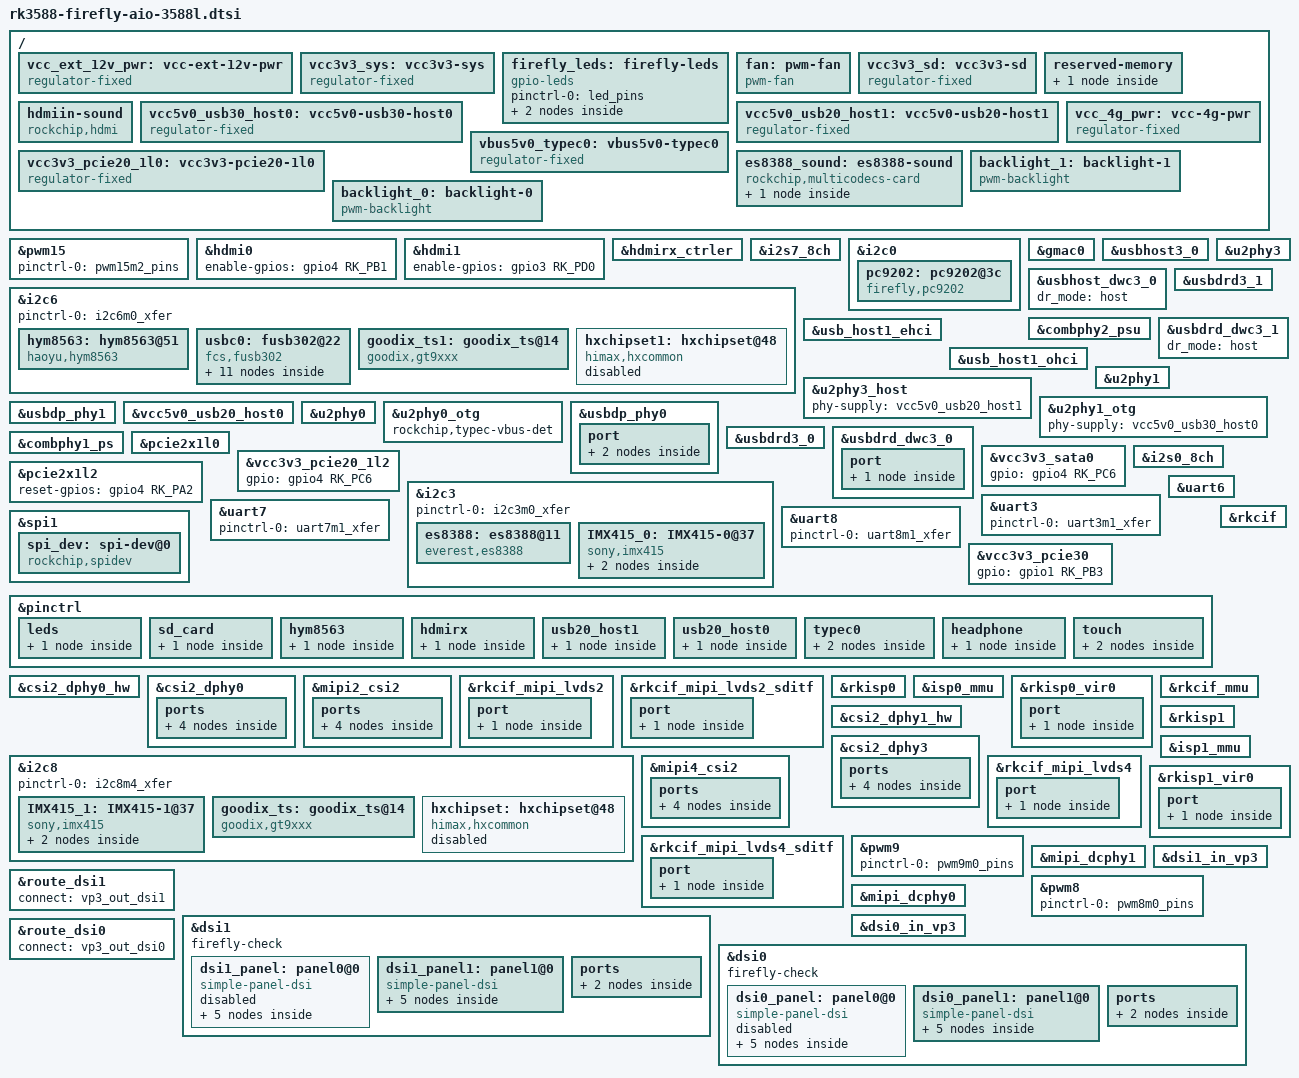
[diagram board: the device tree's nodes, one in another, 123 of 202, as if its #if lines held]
// SPDX-License-Identifier: (GPL-2.0+ OR MIT)
/*
 * Copyright (c) 2022 Rockchip Electronics Co., Ltd.
 *
 */
#include "rk3588-firefly-common.dtsi"

/ {
	vcc_ext_12v_pwr: vcc-ext-12v-pwr {
		status = "okay";
		compatible = "regulator-fixed";
		regulator-name = "vcc_ext_12v_pwr";
		regulator-boot-on;
		regulator-always-on;
		enable-active-high;
		gpio = <&gpio0 RK_PC4 GPIO_ACTIVE_HIGH>;
	};

	vcc3v3_sys: vcc3v3-sys {
		compatible = "regulator-fixed";
		regulator-name = "vcc3v3_sys";
		regulator-always-on;
		regulator-boot-on;
		regulator-min-microvolt = <3300000>;
		regulator-max-microvolt = <3300000>;
		vin-supply = <&vcc12v_dcin>;
	};

#ifdef FF_LEDS
	firefly_leds: firefly-leds {
		status = "okay";
		compatible = "gpio-leds";
		pinctrl-names = "default";
		pinctrl-0 = <&led_pins>;

		power_led: power-led {
			label = ":power";
			default-state = "on";
			gpios = <&gpio3 RK_PB2 GPIO_ACTIVE_HIGH>;
		};

		user_led: user-led {
			label = ":user";
			default-state = "off";
			gpios = <&gpio2 RK_PC3 GPIO_ACTIVE_HIGH>;
		};
	};
#endif

#ifdef FF_FAN
	fan: pwm-fan {
		compatible = "pwm-fan";
		#cooling-cells = <2>;
		pwms = <&pwm15 0 50000 0>;
		cooling-levels = <0 50 100 150 200 255>;
		rockchip,temp-trips = <
			50000   1
			55000   2
			60000   3
			65000   4
			70000   5
		>;
	};
#endif

#ifdef FF_SDCARD
	vcc3v3_sd: vcc3v3-sd {
		compatible = "regulator-fixed";
		regulator-name = "vcc3v3_sd";
		regulator-always-on;
		regulator-boot-on;
		regulator-min-microvolt = <3300000>;
		regulator-max-microvolt = <3300000>;
		enable-active-high;
		gpio = <&gpio4 RK_PB0 GPIO_ACTIVE_HIGH>;
		pinctrl-names = "default";
		pinctrl-0 = <&vcc3v3_sd_en>;
	};
#endif

#ifdef FF_HDMI_RX
	/* If hdmirx node is disabled, delete the reserved-memory node here. */
	reserved-memory {
		#address-cells = <2>;
		#size-cells = <2>;
		ranges;
		
		/* Reserve 256MB memory for hdmirx-controller@fdee0000 */
		cma {
			compatible = "shared-dma-pool";
			reusable;
			reg = <0x0 (256 * 0x100000) 0x0 (256 * 0x100000)>;
			linux,cma-default;
		};
	};

	hdmiin-sound {
		status = "okay";
		compatible = "rockchip,hdmi";
		rockchip,mclk-fs = <128>;
		rockchip,format = "i2s";
		rockchip,bitclock-master = <&hdmirx_ctrler>;
		rockchip,frame-master = <&hdmirx_ctrler>;
		rockchip,card-name = "rockchip,hdmiin";
		rockchip,cpu = <&i2s7_8ch>;
		rockchip,codec = <&hdmirx_ctrler 0>;
		rockchip,jack-det;
	};

#endif

#ifdef FF_USB30_HOST0
	vcc5v0_usb30_host0: vcc5v0-usb30-host0 {
		compatible = "regulator-fixed";
		regulator-name = "vcc5v0_usb30_host0";
		regulator-min-microvolt = <5000000>;
		regulator-max-microvolt = <5000000>;
		regulator-boot-on;
		regulator-always-on;
		enable-active-high;
		vin-supply = <&vcc5v0_sys>;
	};
#endif

#ifdef FF_USB20_HOST1
	vcc5v0_usb20_host1: vcc5v0-usb20-host1 {
		compatible = "regulator-fixed";
		regulator-name = "vcc5v0_usb20_host1";
		regulator-min-microvolt = <5000000>;
		regulator-max-microvolt = <5000000>;
		regulator-boot-on;
		regulator-always-on;
		enable-active-high;
		vin-supply = <&vcc5v0_sys>;
	};
#endif
	
#ifdef FF_TYPEC0
	vbus5v0_typec0: vbus5v0-typec0 {
		compatible = "regulator-fixed";
		regulator-name = "vbus5v0_typec0";
		regulator-min-microvolt = <5000000>;
		regulator-max-microvolt = <5000000>;
		enable-active-high;
		gpio = <&gpio4 RK_PA3 GPIO_ACTIVE_HIGH>;
		pinctrl-names = "default";
		pinctrl-0 = <&vbus5v0_typec0_en>;
		vin-supply = <&vcc5v0_sys>;
	};
#endif

#ifdef FF_PCIE2_1L0_WIFI // for wifi/bt
	vcc3v3_pcie20_1l0: vcc3v3-pcie20-1l0 {
		status = "okay";
		compatible = "regulator-fixed";
		regulator-name = "vcc3v3_pcie20_1l0";
		regulator-min-microvolt = <3300000>;
		regulator-max-microvolt = <3300000>;
		enable-active-high;
		gpio = <&gpio0 RK_PB2 GPIO_ACTIVE_HIGH>;
		startup-delay-us = <5000>;
		vin-supply = <&vcc3v3_sys>;
	};
#endif

#ifdef FF_CODEC_ES8388
	es8388_sound: es8388-sound {
		status = "okay";
		compatible = "rockchip,multicodecs-card";
		rockchip,card-name = "rockchip-es8388";
		hp-det-gpio = <&gpio1 RK_PC4 GPIO_ACTIVE_HIGH>;
		io-channels = <&saradc 3>;
		io-channel-names = "adc-detect";
		keyup-threshold-microvolt = <1800000>;
		poll-interval = <100>;
		hp-con-gpio = <&gpio4 RK_PA7 GPIO_ACTIVE_HIGH>;
		rockchip,pre-power-on-delay-ms = <30>;
		rockchip,post-power-down-delay-ms = <40>;
		rockchip,format = "i2s";
		rockchip,mclk-fs = <256>;
		rockchip,cpu = <&i2s0_8ch>;
		rockchip,codec = <&es8388>;
		rockchip,audio-routing =
			"Headphone", "LOUT1",
			"Headphone", "ROUT1",
			"Speaker", "LOUT2",
			"Speaker", "ROUT2",
			"Headphone", "Headphone Power",
			"Headphone", "Headphone Power",
			"Speaker", "Speaker Power",
			"Speaker", "Speaker Power",
			"LINPUT2", "Main Mic",
			"RINPUT2", "Main Mic",
			"LINPUT1", "Headset Mic",
			"RINPUT1", "Headset Mic";
		pinctrl-names = "default";
		pinctrl-0 = <&hp_det>;
		play-pause-key {
			label = "playpause";
			linux,code = <KEY_PLAYPAUSE>;
			press-threshold-microvolt = <2000>;
		};
	};
#endif

#ifdef FF_4G_MODULE
	vcc_4g_pwr: vcc-4g-pwr {
		status = "okay";
		compatible = "regulator-fixed";
		regulator-name = "vcc_4g_pwr";
		regulator-boot-on;
		regulator-always-on;
		enable-active-high;
		gpio = <&gpio4 RK_PB5 GPIO_ACTIVE_HIGH>;
	};
#endif
};

#ifdef FF_FAN
&pwm15 {
	status = "okay";
	pinctrl-names = "active";
	pinctrl-0 = <&pwm15m2_pins>;
};
#endif

#ifdef FF_HDMI0
&hdmi0 {
	status = "okay";
	enable-gpios = <&gpio4 RK_PB1 GPIO_ACTIVE_HIGH>;
};
#endif

#ifdef FF_HDMI1
&hdmi1 {
	status = "okay";
	enable-gpios = <&gpio3 RK_PD0 GPIO_ACTIVE_HIGH>;
};
#endif

#ifdef FF_HDMI_RX
/* Should work with at least 128MB cma reserved above. */
&hdmirx_ctrler {
	status = "okay";
	#sound-dai-cells = <1>;
	/* Effective level used to trigger HPD: 0-low, 1-high */
	hpd-trigger-level = <1>;
	hdmirx-det-gpios = <&gpio1 RK_PD5 GPIO_ACTIVE_LOW>;
	pinctrl-names = "default";
	pinctrl-0 = <&hdmim1_rx &hdmirx_det>;
};

&i2s7_8ch {
        status = "okay";
};

#endif

#ifdef FF_WATCHDOG
&i2c0 {
	status = "okay";
	pc9202: pc9202@3c {
		status = "okay";
		compatible = "firefly,pc9202";
		reg = <0x3c>;
		wd-en-gpio = <&gpio2 RK_PC5 GPIO_ACTIVE_LOW>;
	};
};
#endif

#ifdef FF_RTC
&i2c6 {
	status = "okay";
	pinctrl-names = "default";
	pinctrl-0 = <&i2c6m0_xfer>;

	hym8563: hym8563@51 {
		status = "okay";
		compatible = "haoyu,hym8563";
		reg = <0x51>;
		#clock-cells = <0>;
		clock-frequency = <32768>;
		clock-output-names = "hym8563";
		pinctrl-names = "default";
		pinctrl-0 = <&hym8563_int>;
		interrupt-parent = <&gpio0>;
		interrupts = <RK_PB0 IRQ_TYPE_LEVEL_LOW>;
		wakeup-source;
	};
};
#endif

#ifdef FF_GMAC0
&gmac0 {
	status = "okay";
	snps,reset-gpio = <&gpio3 RK_PC7 GPIO_ACTIVE_LOW>;
	tx_delay = <0x39>;
};
#endif

//USB3.0 TYPE-A UP
#ifdef FF_USB30_HOST0
&usbhost3_0 {
	status = "okay";
};

&usbhost_dwc3_0 {
	status = "okay";
	dr_mode = "host";
};

&combphy2_psu {
	status = "okay";
};

&vcc5v0_usb20_host1 {
        status = "okay";
        gpio = <&gpio3 RK_PA6 GPIO_ACTIVE_HIGH>;
        pinctrl-names = "default";
        pinctrl-0 = <&vcc5v0_usb20_host1_en>;
        vin-supply = <&vcc5v0_sys>;
};

&usb_host1_ehci {
	status = "okay";
};

&usb_host1_ohci {
	status = "okay";
};

&u2phy3 {
	status = "okay";
};

&u2phy3_host {
	status = "okay";
	phy-supply = <&vcc5v0_usb20_host1>;
};
#endif

//USB3.0 TYPE-A DOWN
#ifdef FF_USB30_HOST1
&usbdrd3_1 {
        status = "okay";
};

&usbdrd_dwc3_1 {
        status = "okay";
	dr_mode = "host";
};

&u2phy1 {
        status = "okay";
};

&u2phy1_otg {
        status = "okay";
        phy-supply = <&vcc5v0_usb30_host0>;
};

&usbdp_phy1 {
        status = "okay";
};
#endif

//USB2.0 HUB
#ifdef FF_USB20_HOST0
&vcc5v0_usb20_host0 {
	status = "okay";
	gpio = <&gpio0 RK_PA0 GPIO_ACTIVE_HIGH>;
	pinctrl-names = "default";
	pinctrl-0 = <&vcc5v0_usb20_host0_en>;
	vin-supply = <&vcc5v0_sys>;
};
#endif

#ifdef FF_TYPEC0
&u2phy0 {
	status = "okay";
};

&u2phy0_otg {
	status = "okay";
	rockchip,typec-vbus-det;
};

&usbdp_phy0 {
	status = "okay";
	orientation-switch;
	svid = <0xff01>;
	sbu1-dc-gpios = <&gpio4 RK_PB2 GPIO_ACTIVE_HIGH>;
	sbu2-dc-gpios = <&gpio4 RK_PB3 GPIO_ACTIVE_HIGH>;

	port {
		#address-cells = <1>;
		#size-cells = <0>;
		usbdp_phy0_orientation_switch: endpoint@0 {
			reg = <0>;
			remote-endpoint = <&usbc0_orien_sw>;
		};

		usbdp_phy0_dp_altmode_mux: endpoint@1 {
			reg = <1>;
			remote-endpoint = <&dp_altmode_mux>;
		};
	};
};

&usbdrd3_0 {
	status = "okay";
};

&usbdrd_dwc3_0 {
	status = "okay";
	dr_mode = "otg";
	usb-role-switch;
	port {
		#address-cells = <1>;
		#size-cells = <0>;
		dwc3_0_role_switch: endpoint@0 {
			reg = <0>;
			remote-endpoint = <&usbc0_role_sw>;
		};
	};
};

&i2c6 {
	status = "okay";
	pinctrl-names = "default";
	pinctrl-0 = <&i2c6m0_xfer>;

	usbc0: fusb302@22 {
		compatible = "fcs,fusb302";
		reg = <0x22>;
		interrupt-parent = <&gpio0>;
		interrupts = <RK_PD3 IRQ_TYPE_LEVEL_LOW>;
		pinctrl-names = "default";
		pinctrl-0 = <&usbc0_int>;
		vbus-supply = <&vbus5v0_typec0>;
		status = "okay";

		ports {
			#address-cells = <1>;
			#size-cells = <0>;

			port@0 {
				reg = <0>;
				usbc0_role_sw: endpoint@0 {
					remote-endpoint = <&dwc3_0_role_switch>;
				};
			};
		};

		usb_con: connector {
			compatible = "usb-c-connector";
			label = "USB-C";
			data-role = "dual";
			power-role = "dual";
			try-power-role = "sink";
			op-sink-microwatt = <1000000>;
			sink-pdos =
				<PDO_FIXED(5000, 1000, PDO_FIXED_USB_COMM)>;
			source-pdos =
				<PDO_FIXED(5000, 3000, PDO_FIXED_USB_COMM)>;

			altmodes {
				#address-cells = <1>;
				#size-cells = <0>;

				altmode@0 {
					reg = <0>;
					svid = /bits/ 16 <0xff01>;
					vdo = <0xffffffff>;
				};
			};

			ports {
				#address-cells = <1>;
				#size-cells = <0>;

				port@0 {
					reg = <0>;
					usbc0_orien_sw: endpoint {
						remote-endpoint = <&usbdp_phy0_orientation_switch>;
					};
				};

				port@1 {
					reg = <1>;
					dp_altmode_mux: endpoint {
						remote-endpoint = <&usbdp_phy0_dp_altmode_mux>;
					};
				};
			};
		};
	};
};
#endif

#ifdef FF_PCIE2_1L0_WIFI // for wifi/bt
&combphy1_ps {
	status = "okay";
};

&pcie2x1l0 {
	status = "okay";
	reset-gpios = <&gpio4 RK_PA5 GPIO_ACTIVE_HIGH>;
	rockchip,skip-scan-in-resume;
	rockchip,perst-inactive-ms = <500>;
	vpcie3v3-supply = <&vcc3v3_pcie20_1l0>;
};
#endif

//M.2 SATA
#ifdef FF_SATA0
&vcc3v3_sata0 {
        gpio = <&gpio4 RK_PC6 GPIO_ACTIVE_HIGH>;
};
#endif

//M.2 PCIe
#ifdef FF_PCIE2_1L2
&vcc3v3_pcie20_1l2 {
	gpio = <&gpio4 RK_PC6 GPIO_ACTIVE_HIGH>;
};
&pcie2x1l2 {
        reset-gpios = <&gpio4 RK_PA2 GPIO_ACTIVE_HIGH>;
};
#endif

#ifdef FF_CODEC_ES8388
&i2c3 {
	status = "okay";
	pinctrl-names = "default";
	pinctrl-0 = <&i2c3m0_xfer>;

	es8388: es8388@11 {
		status = "okay";
		#sound-dai-cells = <0>;
		compatible = "everest,es8388", "everest,es8323";
		reg = <0x11>;
		clocks = <&mclkout_i2s0>;
		clock-names = "mclk";
		assigned-clocks = <&mclkout_i2s0>;
		assigned-clock-rates = <12288000>;
		pinctrl-names = "default";
		pinctrl-0 = <&i2s0_mclk>;
	};
};

&i2s0_8ch {
	status = "okay";
	pinctrl-0 = <&i2s0_lrck
		     &i2s0_sclk
		     &i2s0_sdi0
		     &i2s0_sdo0>;

};

#endif

#ifdef FF_UART3
&uart3 {
	status = "okay";
	pinctrl-names = "default";
	pinctrl-0 = <&uart3m1_xfer>;
};
#endif

#ifdef FF_UART6
&uart6 {
	status = "okay";
	pinctrl-names = "default";
	pinctrl-0 = <&uart6m1_xfer &uart6m1_ctsn &uart6m1_rtsn>;
};
#endif

#ifdef FF_UART7
&uart7 {
	pinctrl-names = "default";
	pinctrl-0 = <&uart7m1_xfer>;
	status = "okay";
};
#endif

#ifdef FF_UART8
&uart8 {
	status = "okay";
	pinctrl-names = "default";
	pinctrl-0 = <&uart8m1_xfer>;
};
#endif

#ifdef FF_SPI1
&spi1 {
	status = "okay";
	pinctrl-0 = <&spi1m2_cs0 &spi1m2_pins>;
	num-cs = <1>;
	max-freq = <50000000>;
	spi_dev: spi-dev@0{
		status = "okay";
		compatible = "rockchip,spidev";
		reg = <0x0>;
		spi-max-frequency = <50000000>;
	};
};
#endif

#ifdef FF_PCIE3_X4
&vcc3v3_pcie30 {
	status = "okay";
	gpio = <&gpio1 RK_PB3 GPIO_ACTIVE_HIGH>;
};

#endif

&pinctrl {
#ifdef FF_LEDS
	leds {
		led_pins: led-pins {
			rockchip,pins = <3 RK_PB2 RK_FUNC_GPIO &pcfg_pull_none>,
					<2 RK_PC3 RK_FUNC_GPIO &pcfg_pull_none>;
		};
	};
#endif

#ifdef FF_SDCARD
	sd_card {
		vcc3v3_sd_en: vcc3v3-sd-en {
			rockchip,pins = <4 RK_PB0 RK_FUNC_GPIO &pcfg_pull_none>;
		};
	};
#endif

#ifdef FF_RTC
	hym8563 {
		hym8563_int: hym8563-int {
			rockchip,pins = <0 RK_PB0 RK_FUNC_GPIO &pcfg_pull_up>;
		};
	};
#endif

#ifdef FF_HDMI_RX
	hdmirx {
		hdmirx_det: hdmirx-det {
			rockchip,pins = <1 RK_PD5 RK_FUNC_GPIO &pcfg_pull_up>;
		};
	};
#endif

#ifdef FF_USB30_HOST0
	usb20_host1 {
		vcc5v0_usb20_host1_en: vcc5v0-usb20-host1-en {
			rockchip,pins = <3 RK_PA6 RK_FUNC_GPIO &pcfg_pull_none>;
		};
	};
#endif

#ifdef FF_USB20_HOST0
	usb20_host0 {
		vcc5v0_usb20_host0_en: vcc5v0-usb20-host-en {
			rockchip,pins = <0 RK_PA0 RK_FUNC_GPIO &pcfg_pull_none>;
		};
	};
#endif

#ifdef FF_TYPEC0
	typec0 {
		vbus5v0_typec0_en: vbus5v0-typec0-en {
			rockchip,pins = <4 RK_PA3 RK_FUNC_GPIO &pcfg_pull_none>;
		};

		usbc0_int: usbc0-int {
			rockchip,pins = <0 RK_PD3 RK_FUNC_GPIO &pcfg_pull_up>;
		};
	};
#endif

#ifdef FF_CODEC_ES8388
	headphone {
		hp_det: hp-det {
			rockchip,pins = <1 RK_PC4 RK_FUNC_GPIO &pcfg_pull_none>;
		};
	};
#endif
};

#ifdef FF_MIPI_CSI0_IMX415
/* ===== inlined from top-level dts: #include "rk3588-firefly-aio-3588l-mipi-csi0-imx415.dtsi" ===== */
// SPDX-License-Identifier: (GPL-2.0+ OR MIT)
/*
 * Copyright (c) 2021 Rockchip Electronics Co., Ltd.
 *
 */

&i2c3 {
	status = "okay";
	pinctrl-names = "default";
	pinctrl-0 = <&i2c3m0_xfer>;

	IMX415_0: IMX415-0@37{
		status = "okay";
		compatible = "sony,imx415";
		reg = <0x37>;
		clocks = <&cru CLK_MIPI_CAMARAOUT_M1>;
		clock-names = "xvclk";
		pinctrl-names = "default";
		pinctrl-0 = <&mipim0_camera1_clk>;
		power-domains = <&power RK3588_PD_VI>;

		reset-gpios = <&gpio2 RK_PB5 GPIO_ACTIVE_LOW>;
	
		rockchip,camera-module-index = <0>;
		rockchip,camera-module-facing = "front";
		rockchip,camera-module-name = "CMK-OT2022-PX1";
		rockchip,camera-module-lens-name = "IR0147-50IRC-8M-F20";

		port {
			imx415_out0: endpoint {
				remote-endpoint = <&mipidphy0_in_ucam1>;
				data-lanes = <1 2 3 4>;
			};
		};
	};
};

&csi2_dphy0_hw {
	status = "okay";
};

&csi2_dphy0 {
	status = "okay";
	ports {
		#address-cells = <1>;
		#size-cells = <0>;
		port@0 {
			reg = <0>;
			#address-cells = <1>;
			#size-cells = <0>;
			mipidphy0_in_ucam1: endpoint@1 {
				reg = <1>;
				remote-endpoint = <&imx415_out0>;
				data-lanes = <1 2 3 4>;
			};
		};
		port@1 {
			reg = <1>;
			#address-cells = <1>;
			#size-cells = <0>;
			csidphy0_out: endpoint@1 {
				reg = <1>;
				remote-endpoint = <&mipi2_csi2_input>;
			};
		};
	};
};

&mipi2_csi2 {
	status = "okay";
	ports {
		#address-cells = <1>;
		#size-cells = <0>;
		port@0 {
			reg = <0>;
			#address-cells = <1>;
			#size-cells = <0>;
			mipi2_csi2_input: endpoint@0 {
				reg = <0>;
				remote-endpoint = <&csidphy0_out>;
			};
		};

		port@1 {
			reg = <1>;
			#address-cells = <1>;
			#size-cells = <0>;

			mipi2_csi2_output: endpoint@1 {
				reg = <1>;
				remote-endpoint = <&cif_mipi2_in0>;
			};
		};
	};
};

&rkcif_mipi_lvds2 {
	status = "okay";
	port {
		cif_mipi2_in0: endpoint {
			remote-endpoint = <&mipi2_csi2_output>;
		};
	};
};

&rkcif_mipi_lvds2_sditf {
	status = "okay";
	port {
		mipi_lvds2_sditf: endpoint {
			remote-endpoint = <&isp0_vir0>;
		};	
	};
};

&rkisp0 {
	status = "okay";
};

&isp0_mmu {
	status = "okay";
};

&rkisp0_vir0 {
	status = "okay";
	port {
		#address-cells = <1>;
		#size-cells = <0>;
		isp0_vir0: endpoint@0 {
			reg = <0>;
			remote-endpoint = <&mipi_lvds2_sditf>;
		};
	};
};

&rkcif {
	status = "okay";
};

&rkcif_mmu {
	status = "okay";
};
#endif

#ifdef FF_MIPI_CSI1_IMX415
/* ===== inlined from top-level dts: #include "rk3588-firefly-aio-3588l-mipi-csi1-imx415.dtsi" ===== */
// SPDX-License-Identifier: (GPL-2.0+ OR MIT)
/*
 * Copyright (c) 2021 Rockchip Electronics Co., Ltd.
 *
 */

&i2c8 {
	status = "okay";
	pinctrl-names = "default";
	pinctrl-0 = <&i2c8m4_xfer>;

	IMX415_1: IMX415-1@37 {
		compatible = "sony,imx415";
		reg = <0x37>;
		clocks = <&cru CLK_MIPI_CAMARAOUT_M3>;
		clock-names = "xvclk";
		pinctrl-names = "default";
		pinctrl-0 = <&mipim0_camera3_clk>;
		power-domains = <&power RK3588_PD_VI>;

		reset-gpios = <&gpio2 RK_PC5 GPIO_ACTIVE_LOW>;

		firefly,clkout-enabled-index = <1>;
		rockchip,camera-module-index = <1>;
		rockchip,camera-module-facing = "back";
		rockchip,camera-module-name = "CMK-OT2022-PX1";
		rockchip,camera-module-lens-name = "IR0147-50IRC-8M-F20";

		port {
			imx415_out1: endpoint {
				remote-endpoint = <&mipidphy3_in_ucam1>;
				data-lanes = <1 2 3 4>;
			};
		};
	};
};

&csi2_dphy1_hw { 
	status = "okay";
};


&csi2_dphy3 {
	status = "okay";
	ports {
		#address-cells = <1>;
		#size-cells = <0>;
		port@0 {
			reg = <0>;
			#address-cells = <1>;
			#size-cells = <0>;
			mipidphy3_in_ucam1: endpoint@1 {
				reg = <1>;
				remote-endpoint = <&imx415_out1>;
				data-lanes = <1 2 3 4>;
			};
		};
		port@1 {
			reg = <1>;
			#address-cells = <1>;
			#size-cells = <0>;

			csidphy3_out: endpoint@1 {
				reg = <1>;
				remote-endpoint = <&mipi4_csi2_input>;
			};
		};
	};
};

&mipi4_csi2 {
	status = "okay";
	ports {
		#address-cells = <1>;
		#size-cells = <0>;

		port@0 {
			reg = <0>;
			#address-cells = <1>;
			#size-cells = <0>;

			mipi4_csi2_input: endpoint@0 {
				reg = <0>;
				remote-endpoint = <&csidphy3_out>;
			};
		};

		port@1 {
			reg = <1>;
			#address-cells = <1>;
			#size-cells = <0>;

			mipi4_csi2_output: endpoint@0 {
				reg = <0>;
				remote-endpoint = <&cif_mipi4_in0>;
			};
		};
	};
};

&rkcif_mipi_lvds4 {
	status = "okay";
	port {
		cif_mipi4_in0: endpoint {
			remote-endpoint = <&mipi4_csi2_output>;
		};
	};
};

&rkcif_mipi_lvds4_sditf {
        status = "okay";
        port {
                mipi_lvds4_sditf: endpoint {
                        remote-endpoint = <&isp1_vir0>;
                };
        };
};

&rkisp1 {
        status = "okay";
};

&isp1_mmu {
        status = "okay";
};

&rkisp1_vir0 {
        status = "okay";
        port {
                #address-cells = <1>;
                #size-cells = <0>;
                isp1_vir0: endpoint@0 {
                        reg = <0>;
                        remote-endpoint = <&mipi_lvds4_sditf>;
                };
        };
};

&rkcif {
	status = "okay";
};

&rkcif_mmu {
	status = "okay";
};
#endif

#if defined(FF_MIPI_DSI0_VP3) && !defined(FF_MIPI_DSI1_VP3)
/* ===== inlined from top-level dts: #include "rk3588-firefly-aio-3588l-mipi-dsi0.dtsi" ===== */
// SPDX-License-Identifier: (GPL-2.0+ OR MIT)
/*
 * Copyright (c) 2021 Rockchip Electronics Co., Ltd.
 *   LCD1_BL_EN  ===> GPIO1_A4
 *   PWM9_M0     ===> backlisht PWM (20kHz)
 *   LCD1_PWR_EN ===> GPIO3_A0
 *   LCD1_RST    ===> GPIO3_A4 (low enable)
 *   TP1_INT     ===> GPIO3_A1
 *   TP1_RST     ===> GPIO3_A5
 *   touch I2C    ===> i2c6_m0
 */

#include <dt-bindings/display/drm_mipi_dsi.h>

/ {
	backlight_1: backlight-1 {
		status = "okay";
		compatible = "pwm-backlight";
		enable-gpios = <&gpio1 RK_PA4 GPIO_ACTIVE_HIGH>;
		pwms = <&pwm9 0 50000 1>;
		brightness-levels = <
			 60  60  60  61  61  61  62  62
			 62  63  63  63  64  64  64  65
			 65  65  66  66  66  67  67  67
			 68  68  68  69  69  69  70  70
			 70  71  71  71  72  72  72  73
			 73  73  74  74  74  75  75  75
			 76  76  76  77  77  77  78  78
			 78  79  79  79  80  80  80  81
			 81  81  82  82  82  83  83  83
			 84  84  84  85  85  85  86  86
			 86  87  87  87  88  88  88  89
			 89  89  90  91  92  93  94  95
			 96  97  98  99 100 101 102 103
			104 105 106 107 108 109 110 111
			112 113 114 115 116 117 118 119
			120 121 122 123 124 125 126 127
			128 129 130 131 132 133 134 135
			136 137 138 139 140 141 142 143
			144 145 146 147 148 149 150 151
			152 153 154 155 156 157 158 159
			160 161 162 163 164 165 166 167
			168 169 170 171 172 173 174 175
			176 177 178 179 180 181 182 183
			184 185 186 187 188 189 190 191
			192 193 194 195 196 197 198 199
			200 201 202 203 204 205 206 207
			208 209 210 211 212 213 214 215
			216 217 218 219 220 221 222 223
			224 225 226 227 228 229 230 231
			232 233 234 235 236 237 238 239
			240 241 242 243 244 245 246 247
			248 249 250 251 252 253 254 255
		>;
		default-brightness-level = <200>;
	};
};

&pwm9 {
	pinctrl-0 = <&pwm9m0_pins>;
	status = "okay";
};

/*
 * mipi_dcphy1 needs to be enabled
 * when dsi1 is enabled
 */
&mipi_dcphy1 {
	status = "okay";
};

&dsi1_in_vp3 {
	status = "okay";
};

&route_dsi1 {
	status = "okay";
	connect = <&vp3_out_dsi1>;
};

&dsi1 {
	status = "okay";
	firefly-check;

	dsi1_panel: panel0@0 {
		status = "disabled";
		compatible = "simple-panel-dsi";
		reg = <0>;
		backlight = <&backlight_1>;

		enable-gpios = <&gpio3 RK_PA0 GPIO_ACTIVE_HIGH>;
		reset-gpios = <&gpio3 RK_PA4 GPIO_ACTIVE_LOW>;

		enable-delay-ms = <50>;
		prepare-delay-ms = <200>;
		reset-delay-ms = <50>;
		init-delay-ms = <55>;
		unprepare-delay-ms = <50>;
		disable-delay-ms = <20>;
		mipi-data-delay-ms = <200>;
		size,width = <120>;
		size,height = <170>;
		dsi,flags = <(MIPI_DSI_MODE_VIDEO | MIPI_DSI_MODE_VIDEO_BURST | MIPI_DSI_MODE_LPM | MIPI_DSI_MODE_NO_EOT_PACKET)>;
		dsi,format = <MIPI_DSI_FMT_RGB888>;
		dsi,lanes = <4>;

		rockchip,touch-nodes = <&goodix_ts1>;

		panel-init-sequence = [
			39 00 04 FF 98 81 01
			99 00 02 00 98
			39 00 04 FF 98 81 03
			15 00 02 01 00
			15 00 02 02 00
			15 00 02 03 55
			15 00 02 04 55
			15 00 02 05 03
			15 00 02 06 06
			15 00 02 07 00
			15 00 02 08 07
			15 00 02 09 00
			15 00 02 0a 00
			15 00 02 0b 00
			15 00 02 0c 00
			15 00 02 0d 00
			15 00 02 0e 00
			15 00 02 0f 00

			15 00 02 10 00
			15 00 02 11 00
			15 00 02 12 00
			15 00 02 13 00
			15 00 02 14 00
			15 00 02 15 00
			15 00 02 16 00
			15 00 02 17 00
			15 00 02 18 00
			15 00 02 19 00
			15 00 02 1a 00
			15 00 02 1b 00
			15 00 02 1c 00
			15 00 02 1d 00
			15 00 02 1e C0
			15 00 02 1f 80

			15 00 02 20 04
			15 00 02 21 03
			15 00 02 22 00
			15 00 02 23 00
			15 00 02 24 00
			15 00 02 25 00
			15 00 02 26 00
			15 00 02 27 00
			15 00 02 28 33
			15 00 02 29 33
			15 00 02 2a 00
			15 00 02 2b 00
			15 00 02 2c 00
			15 00 02 2d 00
			15 00 02 2e 00
			15 00 02 2f 00

			15 00 02 30 00
			15 00 02 31 00
			15 00 02 32 00
			15 00 02 33 00
			15 00 02 34 04
			15 00 02 35 00
			15 00 02 36 00
			15 00 02 37 00
			15 00 02 38 3C
			15 00 02 39 00
			15 00 02 3a 00
			15 00 02 3b 00
			15 00 02 3c 00
			15 00 02 3d 00
			15 00 02 3e 00
			15 00 02 3f 00

			15 00 02 40 00
			15 00 02 41 00
			15 00 02 42 00
			15 00 02 43 00
			15 00 02 44 00

			15 00 02 50 00
			15 00 02 51 11
			15 00 02 52 44
			15 00 02 53 55
			15 00 02 54 88
			15 00 02 55 AB
			15 00 02 56 00
			15 00 02 57 11
			15 00 02 58 22
			15 00 02 59 33
			15 00 02 5a 44
			15 00 02 5b 55
			15 00 02 5c 66
			15 00 02 5d 77
			15 00 02 5e 00
			15 00 02 5f 02

			15 00 02 60 02
			15 00 02 61 0A
			15 00 02 62 09
			15 00 02 63 08
			15 00 02 64 13
			15 00 02 65 12
			15 00 02 66 11
			15 00 02 67 10
			15 00 02 68 0F
			15 00 02 69 0E
			15 00 02 6a 0D
			15 00 02 6b 0C
			15 00 02 6c 06
			15 00 02 6d 07
			15 00 02 6e 02
			15 00 02 6f 02

			15 00 02 70 02
			15 00 02 71 02
			15 00 02 72 02
			15 00 02 73 02
			15 00 02 74 02
			15 00 02 75 02
			15 00 02 76 02
			15 00 02 77 0A
			15 00 02 78 06
			15 00 02 79 07
			15 00 02 7a 10
			15 00 02 7b 11
			15 00 02 7c 12
			15 00 02 7d 13
			15 00 02 7e 0C
			15 00 02 7f 0D

			15 00 02 80 0E
			15 00 02 81 0F
			15 00 02 82 09
			15 00 02 83 08
			15 00 02 84 02
			15 00 02 85 02
			15 00 02 86 02
			15 00 02 87 02
			15 00 02 88 02
			15 00 02 89 02
			15 00 02 8A 02

			39 00 04 FF 98 81 04
			15 00 02 6E 2A
			15 00 02 6F 37
			15 00 02 3A 24
			15 00 02 8D 19
			15 00 02 87 BA
			15 00 02 B2 D1
			15 00 02 88 0B
			15 00 02 38 01
			15 00 02 39 00
			15 00 02 B5 02
			15 00 02 31 25
			15 00 02 3B 98
			39 00 04 FF 98 81 01

			15 00 02 22 0A
			15 00 02 31 0C
			15 00 02 53 40
			15 00 02 55 45
			15 00 02 50 B7
			15 00 02 51 B2
			15 00 02 60 07

			15 00 02 A0 22
			15 00 02 A1 3F
			15 00 02 A2 4E
			15 00 02 A3 17
			15 00 02 A4 1A
			15 00 02 A5 2D
			15 00 02 A6 21
			15 00 02 A7 22
			15 00 02 A8 C4
			15 00 02 A9 1B
			15 00 02 AA 25
			15 00 02 AB A7
			15 00 02 AC 1A
			15 00 02 AD 19
			15 00 02 AE 4B
			15 00 02 AF 1F

			15 00 02 B0 2A
			15 00 02 B1 59
			15 00 02 B2 64
			15 00 02 B3 3F

			15 00 02 C0 22
			15 00 02 C1 48
			15 00 02 C2 59
			15 00 02 C3 15
			15 00 02 C4 15
			15 00 02 C5 28
			15 00 02 C6 1C
			15 00 02 C7 1E
			15 00 02 C8 C4
			15 00 02 C9 1C
			15 00 02 CA 2B
			15 00 02 CB A3
			15 00 02 CC 1F
			15 00 02 CD 1E
			15 00 02 CE 52
			15 00 02 CF 24

			15 00 02 D0 2A
			15 00 02 D1 58
			15 00 02 D2 68
			15 00 02 D3 3F
			39 00 04 FF 98 81 00
			05 78 01 11			 //Delay 120ms
			05 14 01 29			 //Delay 20ms
		];

		panel-exit-sequence = [
			39 00 04 FF 98 81 00		//page0
			05 14 01 28				//Delay 20ms
			05 78 01 10				//Delay 120ms
		];

		disp_timings: display-timings {
			native-mode = <&dsi_timing>;
			dsi_timing: timing {
				clock-frequency = <70000000>;//<80000000>;
				hactive = <800>;//<768>;
				vactive = <1280>;
				hsync-len = <20>;   //20, 50,10
				hback-porch = <20>; //50, 56,10
				hfront-porch = <40>;//50, 30,180
				vsync-len = <4>;//4
				vback-porch = <20>;//4
				vfront-porch = <20>;//8
				hsync-active = <0>;
				vsync-active = <0>;
				de-active = <0>;
				pixelclk-active = <0>;
			};
		};

		ports {
			#address-cells = <1>;
			#size-cells = <0>;

			port@0 {
				reg = <0>;
				panel_in_dsi1: endpoint {
					remote-endpoint = <&dsi1_out_panel>;
				};
			};
		};
	};

	dsi1_panel1: panel1@0 {
		status = "okay";
		compatible = "simple-panel-dsi";
		reg = <0>;
		backlight = <&backlight_1>;

		enable-gpios = <&gpio3 RK_PA0 GPIO_ACTIVE_HIGH>;
		reset-gpios = <&gpio3 RK_PA4 GPIO_ACTIVE_LOW>;

		enable-delay-ms = <50>;
		prepare-delay-ms = <200>;
		reset-delay-ms = <50>;
		init-delay-ms = <55>;
		unprepare-delay-ms = <50>;
		disable-delay-ms = <20>;
		mipi-data-delay-ms = <200>;
		size,width = <120>;
		size,height = <170>;
		dsi,flags = <(MIPI_DSI_MODE_VIDEO | MIPI_DSI_MODE_VIDEO_BURST | MIPI_DSI_MODE_LPM | MIPI_DSI_MODE_NO_EOT_PACKET)>;
		dsi,format = <MIPI_DSI_FMT_RGB888>;
		dsi,lanes = <4>;

		// main display auto switch
		panel-read-id-sequence = [
			39 00 04 FF 98 81 01
		];
		id-reg = <0x00>;
		id = [98];
		
		rockchip,touch-nodes = <&goodix_ts1>;

		panel-init-sequence = [
			05 78 01 11
			05 32 01 29
		];

		panel-exit-sequence = [
			05 00 01 28
			05 00 01 10
		];

		display-timings {
			native-mode = <&dsi1_timing1>;
			dsi1_timing1: timing0 {
				clock-frequency = <72600000>;
				hactive = <800>;
				vactive = <1280>;
				hsync-len = <14>;
				hback-porch = <26>;
				hfront-porch = <32>;
				vsync-len = <8>;
				vback-porch = <20>;
				vfront-porch = <80>;
				hsync-active = <0>;
				vsync-active = <0>;
				de-active = <0>;
				pixelclk-active = <0>;
			};
		};

		ports {
			#address-cells = <1>;
			#size-cells = <0>;

			port@0 {
				reg = <0>;
				panel1_in_dsi1: endpoint {
					remote-endpoint = <&dsi1_out_panel>;
				};
			};
		};
	};

	ports {
		#address-cells = <1>;
		#size-cells = <0>;

		port@1 {
			reg = <1>;
			dsi1_out_panel: endpoint {
			remote-endpoint = <&panel1_in_dsi1>;
			};
		};
	};
};

&i2c6{
	status = "okay";
	pinctrl-names = "default";
	pinctrl-0 = <&i2c6m0_xfer>;

	goodix_ts1: goodix_ts@14 {
		status = "okay";
		compatible = "goodix,gt9xxx";
		reg = <0x14>;
		interrupt-parent = <&gpio3>;
		interrupts = <RK_PA1 IRQ_TYPE_LEVEL_LOW>;
		reset-gpios = <&gpio3 RK_PA5 GPIO_ACTIVE_HIGH>;
		irq-gpios = <&gpio3 RK_PA1 IRQ_TYPE_LEVEL_LOW>;
		irq-flags = <2>; /* 1 rising, 2 falling */
		pinctrl-names = "default";
		pinctrl-0 = <&touch_int1>;
		touchscreen-size-x = <800>;
		touchscreen-size-y = <1280>;
		goodix,slide-wakeup = <0>;
		goodix,type-a-report = <1>;
		goodix,driver-send-cfg = <1>;
		goodix,resume-in-workqueue = <0>;
		goodix,int-sync = <1>;
		goodix,esd-protect = <1>;
		goodix,auto-update-cfg = <1>;
		goodix,auto-update = <0>;
		goodix,power-off-sleep = <0>;
		goodix,pen-suppress-finger = <0>;
		goodix,has-pen = <0>;

		goodix,cfg-group2 = [
			62 20 03 00 05 0A 35 00 01
			0A 28 0F 50 3C 03 05 00 00
			00 00 00 00 06 18 1A 1E 14
			90 30 AA 37 39 12 0C 00 00
			00 1A 02 2D 00 00 00 00 00
			00 00 00 07 00 00 28 4B 94
			D5 02 07 00 00 04 9A 2A 00
			8C 30 00 81 36 00 76 3E 00
			6E 46 00 6E 00 00 00 00 00
			00 00 00 00 00 00 00 00 00
			00 00 00 00 00 00 00 00 00
			00 00 00 00 00 02 00 00 00
			00 00 00 00 19 18 17 16 15
			14 11 10 0F 0E 0D 0C 09 08
			07 06 05 04 01 00 00 00 00
			00 00 00 00 00 00 00 14 13
			12 11 10 0F 0E 0D 0C 0A 08
			07 06 04 02 00 19 1B 1C 1E
			1F 20 21 22 23 24 25 26 27
			28 29 2A 00 00 00 00 00 00
			00 00 00 00 D8 01];
	};

	hxchipset1: hxchipset@48 {
		status = "disabled";
		compatible = "himax,hxcommon";
		reg = <0x48>;

		himax,rst-gpio = <&gpio3 RK_PA5 GPIO_ACTIVE_HIGH>;
		himax,irq-gpio = <&gpio3 RK_PA1 IRQ_TYPE_LEVEL_HIGH>;
		pinctrl-names = "default";
		pinctrl-0 = <&touch_int1>;

		himax,panel-coords = <0 800 0 1280>;      // touch range
		himax,display-coords = <0 800 0 1280>;    // resolution
		report_type = <1>;
	};
};

&pinctrl {
	touch {
		touch_int1: touch-int1 {
			rockchip,pins = <3 RK_PA1 RK_FUNC_GPIO &pcfg_pull_up>;
		};
	};
};
#endif

#if defined(FF_MIPI_DSI1_VP3) && !defined(FF_MIPI_DSI0_VP3)
/* ===== inlined from top-level dts: #include "rk3588-firefly-aio-3588l-mipi-dsi1.dtsi" ===== */
// SPDX-License-Identifier: (GPL-2.0+ OR MIT)
/*
 * Copyright (c) 2021 Rockchip Electronics Co., Ltd.
 *
 *   LCD0_BL_EN  ===> GPIO1_B1
 *   PWM8_M0     ===> backlight PWM (20kHz)
 *   LCD0_PWR_EN ===> GPIO3_B7
 *   LCD0_RST    ===> GPIO3_B3 (low enable)
 *   TP0_INT     ===> GPIO3_B1
 *   TP0_RST     ===> GPIO3_B4
 *   touch I2C    ===> i2c8_m4
 */

#include <dt-bindings/display/drm_mipi_dsi.h>

/ {
	backlight_0: backlight-0 {
		status = "okay";
		compatible = "pwm-backlight";
		enable-gpios = <&gpio1 RK_PB1 GPIO_ACTIVE_HIGH>;
		pwms = <&pwm8 0 50000 1>;
		brightness-levels = <
			 60  60  60  61  61  61  62  62
			 62  63  63  63  64  64  64  65
			 65  65  66  66  66  67  67  67
			 68  68  68  69  69  69  70  70
			 70  71  71  71  72  72  72  73
			 73  73  74  74  74  75  75  75
			 76  76  76  77  77  77  78  78
			 78  79  79  79  80  80  80  81
			 81  81  82  82  82  83  83  83
			 84  84  84  85  85  85  86  86
			 86  87  87  87  88  88  88  89
			 89  89  90  91  92  93  94  95
			 96  97  98  99 100 101 102 103
			104 105 106 107 108 109 110 111
			112 113 114 115 116 117 118 119
			120 121 122 123 124 125 126 127
			128 129 130 131 132 133 134 135
			136 137 138 139 140 141 142 143
			144 145 146 147 148 149 150 151
			152 153 154 155 156 157 158 159
			160 161 162 163 164 165 166 167
			168 169 170 171 172 173 174 175
			176 177 178 179 180 181 182 183
			184 185 186 187 188 189 190 191
			192 193 194 195 196 197 198 199
			200 201 202 203 204 205 206 207
			208 209 210 211 212 213 214 215
			216 217 218 219 220 221 222 223
			224 225 226 227 228 229 230 231
			232 233 234 235 236 237 238 239
			240 241 242 243 244 245 246 247
			248 249 250 251 252 253 254 255
		>;
		default-brightness-level = <200>;
	};
};

&pwm8 {
	pinctrl-0 = <&pwm8m0_pins>;
	status = "okay";
};

/*
 * mipi_dcphy0 needs to be enabled
 * when dsi0 is enabled
 */
&mipi_dcphy0 {
	status = "okay";
};

&dsi0_in_vp3 {
	status = "okay";
};

&route_dsi0 {
	status = "okay";
	connect = <&vp3_out_dsi0>;
};

&dsi0 {
	status = "okay";
	firefly-check;

	dsi0_panel: panel0@0 {
		status = "disabled";
		compatible = "simple-panel-dsi";
		reg = <0>;
		backlight = <&backlight_0>;

		enable-gpios = <&gpio3 RK_PB7 GPIO_ACTIVE_HIGH>;
		reset-gpios = <&gpio3 RK_PB3 GPIO_ACTIVE_LOW>;

		enable-delay-ms = <50>;
		prepare-delay-ms = <200>;
		reset-delay-ms = <50>;
		init-delay-ms = <55>;
		unprepare-delay-ms = <50>;
		disable-delay-ms = <20>;
		mipi-data-delay-ms = <200>;
		size,width = <120>;
		size,height = <170>;
		dsi,flags = <(MIPI_DSI_MODE_VIDEO | MIPI_DSI_MODE_VIDEO_BURST | MIPI_DSI_MODE_LPM | MIPI_DSI_MODE_NO_EOT_PACKET)>;
		dsi,format = <MIPI_DSI_FMT_RGB888>;
		dsi,lanes = <4>;
		rockchip,touch-nodes = <&goodix_ts>;

		panel-init-sequence = [
			39 00 04 FF 98 81 01
			99 00 02 00 98
			39 00 04 FF 98 81 03
			15 00 02 01 00
			15 00 02 02 00
			15 00 02 03 55
			15 00 02 04 55
			15 00 02 05 03
			15 00 02 06 06
			15 00 02 07 00
			15 00 02 08 07
			15 00 02 09 00
			15 00 02 0a 00
			15 00 02 0b 00
			15 00 02 0c 00
			15 00 02 0d 00
			15 00 02 0e 00
			15 00 02 0f 00

			15 00 02 10 00
			15 00 02 11 00
			15 00 02 12 00
			15 00 02 13 00
			15 00 02 14 00
			15 00 02 15 00
			15 00 02 16 00
			15 00 02 17 00
			15 00 02 18 00
			15 00 02 19 00
			15 00 02 1a 00
			15 00 02 1b 00
			15 00 02 1c 00
			15 00 02 1d 00
			15 00 02 1e C0
			15 00 02 1f 80

			15 00 02 20 04
			15 00 02 21 03
			15 00 02 22 00
			15 00 02 23 00
			15 00 02 24 00
			15 00 02 25 00
			15 00 02 26 00
			15 00 02 27 00
			15 00 02 28 33
			15 00 02 29 33
			15 00 02 2a 00
			15 00 02 2b 00
			15 00 02 2c 00
			15 00 02 2d 00
			15 00 02 2e 00
			15 00 02 2f 00

			15 00 02 30 00
			15 00 02 31 00
			15 00 02 32 00
			15 00 02 33 00
			15 00 02 34 04
			15 00 02 35 00
			15 00 02 36 00
			15 00 02 37 00
			15 00 02 38 3C
			15 00 02 39 00
			15 00 02 3a 00
			15 00 02 3b 00
			15 00 02 3c 00
			15 00 02 3d 00
			15 00 02 3e 00
			15 00 02 3f 00

			15 00 02 40 00
			15 00 02 41 00
			15 00 02 42 00
			15 00 02 43 00
			15 00 02 44 00

			15 00 02 50 00
			15 00 02 51 11
			15 00 02 52 44
			15 00 02 53 55
			15 00 02 54 88
			15 00 02 55 AB
			15 00 02 56 00
			15 00 02 57 11
			15 00 02 58 22
			15 00 02 59 33
			15 00 02 5a 44
			15 00 02 5b 55
			15 00 02 5c 66
			15 00 02 5d 77
			15 00 02 5e 00
			15 00 02 5f 02

			15 00 02 60 02
			15 00 02 61 0A
			15 00 02 62 09
			15 00 02 63 08
			15 00 02 64 13
			15 00 02 65 12
			15 00 02 66 11
			15 00 02 67 10
			15 00 02 68 0F
			15 00 02 69 0E
			15 00 02 6a 0D
			15 00 02 6b 0C
			15 00 02 6c 06
			15 00 02 6d 07
			15 00 02 6e 02
			15 00 02 6f 02

			15 00 02 70 02
			15 00 02 71 02
			15 00 02 72 02
			15 00 02 73 02
			15 00 02 74 02
			15 00 02 75 02
			15 00 02 76 02
			15 00 02 77 0A
			15 00 02 78 06
			15 00 02 79 07
			15 00 02 7a 10
			15 00 02 7b 11
			15 00 02 7c 12
			15 00 02 7d 13
			15 00 02 7e 0C
			15 00 02 7f 0D

			15 00 02 80 0E
			15 00 02 81 0F
			15 00 02 82 09
			15 00 02 83 08
			15 00 02 84 02
			15 00 02 85 02
			15 00 02 86 02
			15 00 02 87 02
			15 00 02 88 02
			15 00 02 89 02
			15 00 02 8A 02

			39 00 04 FF 98 81 04
			15 00 02 6E 2A
			15 00 02 6F 37
			15 00 02 3A 24
			15 00 02 8D 19
			15 00 02 87 BA
			15 00 02 B2 D1
			15 00 02 88 0B
			15 00 02 38 01
			15 00 02 39 00
			15 00 02 B5 02
			15 00 02 31 25
			15 00 02 3B 98
			39 00 04 FF 98 81 01

			15 00 02 22 0A
			15 00 02 31 0C
			15 00 02 53 40
			15 00 02 55 45
			15 00 02 50 B7
			15 00 02 51 B2
			15 00 02 60 07

			15 00 02 A0 22
			15 00 02 A1 3F
			15 00 02 A2 4E
			15 00 02 A3 17
			15 00 02 A4 1A
			15 00 02 A5 2D
			15 00 02 A6 21
			15 00 02 A7 22
			15 00 02 A8 C4
			15 00 02 A9 1B
			15 00 02 AA 25
			15 00 02 AB A7
			15 00 02 AC 1A
			15 00 02 AD 19
			15 00 02 AE 4B
			15 00 02 AF 1F

			15 00 02 B0 2A
			15 00 02 B1 59
			15 00 02 B2 64
			15 00 02 B3 3F

			15 00 02 C0 22
			15 00 02 C1 48
			15 00 02 C2 59
			15 00 02 C3 15
			15 00 02 C4 15
			15 00 02 C5 28
			15 00 02 C6 1C
			15 00 02 C7 1E
			15 00 02 C8 C4
			15 00 02 C9 1C
			15 00 02 CA 2B
			15 00 02 CB A3
			15 00 02 CC 1F
			15 00 02 CD 1E
			15 00 02 CE 52
			15 00 02 CF 24

			15 00 02 D0 2A
			15 00 02 D1 58
			15 00 02 D2 68
			15 00 02 D3 3F
			39 00 04 FF 98 81 00
			05 78 01 11			 //Delay 120ms
			05 14 01 29			 //Delay 20ms
		];

		panel-exit-sequence = [
			39 00 04 FF 98 81 00		//page0
			05 14 01 28				//Delay 20ms
			05 78 01 10				//Delay 120ms
		];

		disp_timings: display-timings {
			native-mode = <&dsi_timing>;
			dsi_timing: timing {
				clock-frequency = <70000000>;//<80000000>;
				hactive = <800>;//<768>;
				vactive = <1280>;
				hsync-len = <20>;   //20, 50,10
				hback-porch = <20>; //50, 56,10
				hfront-porch = <40>;//50, 30,180
				vsync-len = <4>;//4
				vback-porch = <20>;//4
				vfront-porch = <20>;//8
				hsync-active = <0>;
				vsync-active = <0>;
				de-active = <0>;
				pixelclk-active = <0>;
			};
		};

		ports {
			#address-cells = <1>;
			#size-cells = <0>;

			port@0 {
				reg = <0>;
				panel_in_dsi0: endpoint {
					remote-endpoint = <&dsi0_out_panel>;
				};
			};
		};
	};

	/*
	 * panel1: 10.1" M101014-BE45-A1, self-init panel
	 * (only sleep-out / display-on commands).
	 */
	dsi0_panel1: panel1@0 {
		status = "okay";
		compatible = "simple-panel-dsi";
		reg = <0>;
		backlight = <&backlight_0>;

		enable-gpios = <&gpio3 RK_PB7 GPIO_ACTIVE_HIGH>;
		reset-gpios = <&gpio3 RK_PB3 GPIO_ACTIVE_LOW>;

		enable-delay-ms = <50>;
		prepare-delay-ms = <200>;
		reset-delay-ms = <50>;
		init-delay-ms = <55>;
		unprepare-delay-ms = <50>;
		disable-delay-ms = <20>;
		mipi-data-delay-ms = <200>;
		size,width = <120>;
		size,height = <170>;
		dsi,flags = <(MIPI_DSI_MODE_VIDEO | MIPI_DSI_MODE_VIDEO_BURST | MIPI_DSI_MODE_LPM | MIPI_DSI_MODE_NO_EOT_PACKET)>;
		dsi,format = <MIPI_DSI_FMT_RGB888>;
		dsi,lanes = <4>;

		// main display auto switch
		panel-read-id-sequence = [
			39 00 04 FF 98 81 01
		];
		id-reg = <0x00>;
		id = [98];
		
		rockchip,touch-nodes = <&goodix_ts>;

		panel-init-sequence = [
			05 78 01 11
			05 32 01 29
		];

		panel-exit-sequence = [
			05 00 01 28
			05 00 01 10
		];

		display-timings {
			native-mode = <&dsi0_timing1>;
			dsi0_timing1: timing0 {
				clock-frequency = <72600000>;
				hactive = <800>;
				vactive = <1280>;
				hsync-len = <14>;
				hback-porch = <26>;
				hfront-porch = <32>;
				vsync-len = <8>;
				vback-porch = <20>;
				vfront-porch = <80>;
				hsync-active = <0>;
				vsync-active = <0>;
				de-active = <0>;
				pixelclk-active = <0>;
			};
		};

		ports {
			#address-cells = <1>;
			#size-cells = <0>;

			port@0 {
				reg = <0>;
				panel1_in_dsi0: endpoint {
					remote-endpoint = <&dsi0_out_panel>;
				};
			};
		};
	};

	ports {
		#address-cells = <1>;
		#size-cells = <0>;

		port@1 {
			reg = <1>;
			dsi0_out_panel: endpoint {
			remote-endpoint = <&panel1_in_dsi0>;
			};
		};
	};
};

&i2c8{
	status = "okay";
	pinctrl-names = "default";
	pinctrl-0 = <&i2c8m4_xfer>;

	goodix_ts: goodix_ts@14 {
		status = "okay";
		compatible = "goodix,gt9xxx";
		reg = <0x14>;
		interrupt-parent = <&gpio3>;
		interrupts = <RK_PB1 IRQ_TYPE_LEVEL_LOW>;
		reset-gpios = <&gpio3 RK_PB4 GPIO_ACTIVE_HIGH>;
		irq-gpios = <&gpio3 RK_PB1 IRQ_TYPE_LEVEL_LOW>;
		irq-flags = <2>; /* 1 rising, 2 falling */
		pinctrl-names = "default";
		pinctrl-0 = <&touch_int0>;
		touchscreen-size-x = <800>;
		touchscreen-size-y = <1280>;
		goodix,slide-wakeup = <0>;
		goodix,type-a-report = <1>;
		goodix,driver-send-cfg = <1>;
		goodix,resume-in-workqueue = <0>;
		goodix,int-sync = <1>;
		goodix,esd-protect = <1>;
		goodix,auto-update-cfg = <1>;
		goodix,auto-update = <0>;
		goodix,power-off-sleep = <0>;
		goodix,pen-suppress-finger = <0>;
		goodix,has-pen = <0>;

		goodix,cfg-group2 = [
			62 20 03 00 05 0A 35 00 01
			0A 28 0F 50 3C 03 05 00 00
			00 00 00 00 06 18 1A 1E 14
			90 30 AA 37 39 12 0C 00 00
			00 1A 02 2D 00 00 00 00 00
			00 00 00 07 00 00 28 4B 94
			D5 02 07 00 00 04 9A 2A 00
			8C 30 00 81 36 00 76 3E 00
			6E 46 00 6E 00 00 00 00 00
			00 00 00 00 00 00 00 00 00
			00 00 00 00 00 00 00 00 00
			00 00 00 00 00 02 00 00 00
			00 00 00 00 19 18 17 16 15
			14 11 10 0F 0E 0D 0C 09 08
			07 06 05 04 01 00 00 00 00
			00 00 00 00 00 00 00 14 13
			12 11 10 0F 0E 0D 0C 0A 08
			07 06 04 02 00 19 1B 1C 1E
			1F 20 21 22 23 24 25 26 27
			28 29 2A 00 00 00 00 00 00
			00 00 00 00 D8 01];
	};

	hxchipset: hxchipset@48 {
		status = "disabled";
		compatible = "himax,hxcommon";
		reg = <0x48>;

		himax,rst-gpio = <&gpio3 RK_PB4 GPIO_ACTIVE_HIGH>;
		himax,irq-gpio = <&gpio3 RK_PB1 IRQ_TYPE_LEVEL_HIGH>;
		pinctrl-names = "default";
		pinctrl-0 = <&touch_int0>;

		himax,panel-coords = <0 800 0 1280>;      // touch range
		himax,display-coords = <0 800 0 1280>;    // resolution
		report_type = <1>;
	};
};

&pinctrl {
	touch {
		touch_int0: touch-int0 {
			rockchip,pins = <3 RK_PB1 RK_FUNC_GPIO &pcfg_pull_up>;
		};
	};
};
#endif
